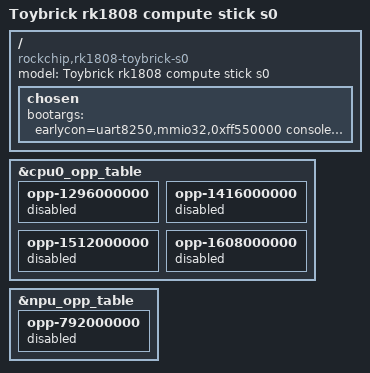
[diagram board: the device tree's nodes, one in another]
// SPDX-License-Identifier: (GPL-2.0+ OR MIT)
/*
 * Copyright (c) 2018 Fuzhou Rockchip Electronics Co., Ltd
 */

/dts-v1/;
#include "rk1808-toybrick.dtsi"

/ {
	model = "Toybrick rk1808 compute stick s0";
	compatible = "rockchip,rk1808-toybrick-s0", "rockchip,rk1808";

	chosen {
		bootargs = "earlycon=uart8250,mmio32,0xff550000 console=ttyFIQ0 swiotlb=1 coherent_pool=1m swiotlb=1 kpti=0";
	};
};

&cpu0_opp_table {
	opp-1296000000 {
		status = "disabled";
	};
	opp-1416000000 {
		status = "disabled";
	};
	opp-1512000000 {
		status = "disabled";
	};
	opp-1608000000 {
		status = "disabled";
	};
};

&npu_opp_table {
	opp-792000000 	{
		status = "disabled";
	};
};

